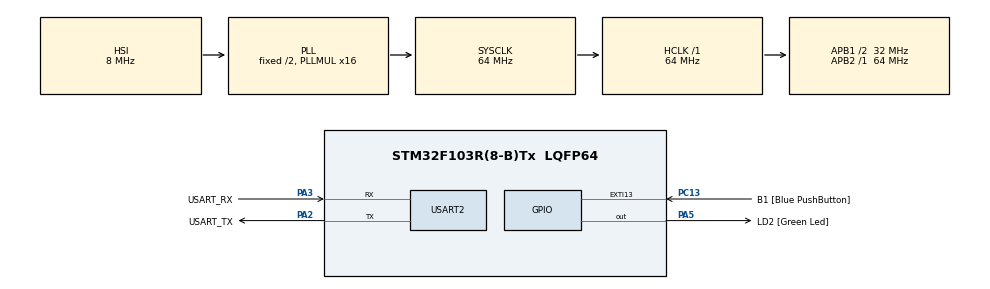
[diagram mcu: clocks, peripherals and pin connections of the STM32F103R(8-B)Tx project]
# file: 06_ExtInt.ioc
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Mcu.Family=STM32F1
Mcu.Name=STM32F103R(8-B)Tx
Mcu.Package=LQFP64
NVIC.EXTI15_10_IRQn=true\:0\:0\:false\:false\:true\:true\:true\:true
NVIC.PriorityGroup=NVIC_PRIORITYGROUP_4
PA13.GPIO_Label=TMS
PA13.Mode=Serial_Wire
PA13.Signal=SYS_JTMS-SWDIO
PA14.GPIO_Label=TCK
PA14.Mode=Serial_Wire
PA14.Signal=SYS_JTCK-SWCLK
PA2.GPIO_Label=USART_TX
PA2.GPIO_Mode=GPIO_MODE_AF_PP
PA2.GPIO_PuPd=GPIO_NOPULL
PA2.GPIO_Speed=GPIO_SPEED_FREQ_LOW
PA2.Mode=Asynchronous
PA2.Signal=USART2_TX
PA3.GPIO_Label=USART_RX
PA3.GPIO_Mode=GPIO_MODE_INPUT
PA3.GPIO_PuPd=GPIO_NOPULL
PA3.Mode=Asynchronous
PA3.Signal=USART2_RX
PA5.GPIO_Label=LD2 [Green Led]
PA5.GPIO_ModeDefaultOutputPP=GPIO_MODE_OUTPUT_PP
PA5.GPIO_PuPd=GPIO_NOPULL
PA5.GPIO_Speed=GPIO_SPEED_FREQ_LOW
PA5.Signal=GPIO_Output
PB3.GPIO_Label=SWO
PB3.Signal=SYS_JTDO-TRACESWO
PC13-TAMPER-RTC.GPIO_Label=B1 [Blue PushButton]
PC13-TAMPER-RTC.GPIO_ModeDefaultEXTI=GPIO_MODE_IT_FALLING
PC13-TAMPER-RTC.GPIO_PuPd=GPIO_NOPULL
PC13-TAMPER-RTC.Signal=GPXTI13
PC14-OSC32_IN.Mode=LSE-External-Oscillator
PC14-OSC32_IN.Signal=RCC_OSC32_IN
PC15-OSC32_OUT.Mode=LSE-External-Oscillator
PC15-OSC32_OUT.Signal=RCC_OSC32_OUT
PD0-OSC_IN.Mode=HSE-External-Clock-Source
PD0-OSC_IN.Signal=RCC_OSC_IN
PD1-OSC_OUT.Mode=HSE-External-Clock-Source
PD1-OSC_OUT.Signal=RCC_OSC_OUT
ProjectManager.HeapSize=0x200
ProjectManager.StackSize=0x400
ProjectManager.TargetToolchain=STM32CubeIDE
RCC.AHBFreq_Value=64000000
RCC.APB1CLKDivider=RCC_HCLK_DIV2
RCC.APB1Freq_Value=32000000
RCC.APB1TimFreq_Value=64000000
RCC.APB2Freq_Value=64000000
RCC.APB2TimFreq_Value=64000000
RCC.HCLKFreq_Value=64000000
RCC.PLLMUL=RCC_PLL_MUL16
RCC.RTCClockSelection=RCC_RTCCLKSOURCE_LSE
RCC.SYSCLKFreq_VALUE=64000000
RCC.SYSCLKSource=RCC_SYSCLKSOURCE_PLLCLK
RCC.USBFreq_Value=64000000
USART2.VirtualMode=VM_ASYNC
board=NUCLEO-F103RB

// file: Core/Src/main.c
/* USER CODE BEGIN Header */
/**
  ******************************************************************************
  * @file           : main.c
  * @brief          : Main program body
  ******************************************************************************
  * @attention
  *
  * Copyright (c) 2026 STMicroelectronics.
  * All rights reserved.
  *
  * This software is licensed under terms that can be found in the LICENSE file
  * in the root directory of this software component.
  * If no LICENSE file comes with this software, it is provided AS-IS.
  *
  ******************************************************************************
  */
/**
 * 06_ExtInt  —  [계층: HAL + EXTI/NVIC]  버튼(B1, PC13) 외부 인터럽트로 LED(LD2) 토글
 *
 * 신호 경로: PC13 -> EXTI13 (하강 에지) -> NVIC EXTI15_10_IRQn -> ISR -> HAL 콜백
 *
 * 하드웨어 대응 (RM0008)
 *   AFIO_EXTICR4  : EXTI13 의 입력 포트를 PC 로 선택
 *   EXTI_IMR / EXTI_FTSR : EXTI13 인터럽트 마스크 해제 / 하강 에지 트리거
 *   EXTI_PR       : 펜딩 비트 (HAL_GPIO_EXTI_IRQHandler 가 1을 써서 지움)
 *   NVIC_ISER     : EXTI15_10_IRQn 허용 (HAL_NVIC_EnableIRQ)
 *
 * ISR 과 콜백의 구분
 *   EXTI15_10_IRQHandler()     (stm32f1xx_it.c) : 진짜 ISR. HAL_GPIO_EXTI_IRQHandler() 를 호출
 *   HAL_GPIO_EXTI_Callback()   (이 파일)        : 사용자 콜백. ISR 문맥에서 실행되므로 짧게 끝낼 것
 */
/* USER CODE END Header */
#include "main.h"

UART_HandleTypeDef huart2;

void SystemClock_Config(void);
static void MX_GPIO_Init(void);
static void MX_USART2_UART_Init(void);

int main(void)
{

  /* MCU Configuration--------------------------------------------------------*/

  /* Reset of all peripherals, Initializes the Flash interface and the Systick. */
  HAL_Init();

  /* Configure the system clock */
  SystemClock_Config();

  /* Initialize all configured peripherals */
  MX_GPIO_Init();
  MX_USART2_UART_Init();

  /* Infinite loop */
  while (1)
  {

  }
}

void SystemClock_Config(void)
{
  RCC_OscInitTypeDef RCC_OscInitStruct = {0};
  RCC_ClkInitTypeDef RCC_ClkInitStruct = {0};

  /** Initializes the RCC Oscillators according to the specified parameters
  * in the RCC_OscInitTypeDef structure.
  */
  RCC_OscInitStruct.OscillatorType = RCC_OSCILLATORTYPE_HSI;
  RCC_OscInitStruct.HSIState = RCC_HSI_ON;
  RCC_OscInitStruct.HSICalibrationValue = RCC_HSICALIBRATION_DEFAULT;
  RCC_OscInitStruct.PLL.PLLState = RCC_PLL_ON;
  RCC_OscInitStruct.PLL.PLLSource = RCC_PLLSOURCE_HSI_DIV2;
  RCC_OscInitStruct.PLL.PLLMUL = RCC_PLL_MUL16;
  if (HAL_RCC_OscConfig(&RCC_OscInitStruct) != HAL_OK)
  {
    Error_Handler();
  }

  /** Initializes the CPU, AHB and APB buses clocks
  */
  RCC_ClkInitStruct.ClockType = RCC_CLOCKTYPE_HCLK|RCC_CLOCKTYPE_SYSCLK
                              |RCC_CLOCKTYPE_PCLK1|RCC_CLOCKTYPE_PCLK2;
  RCC_ClkInitStruct.SYSCLKSource = RCC_SYSCLKSOURCE_PLLCLK;
  RCC_ClkInitStruct.AHBCLKDivider = RCC_SYSCLK_DIV1;
  RCC_ClkInitStruct.APB1CLKDivider = RCC_HCLK_DIV2;
  RCC_ClkInitStruct.APB2CLKDivider = RCC_HCLK_DIV1;

  if (HAL_RCC_ClockConfig(&RCC_ClkInitStruct, FLASH_LATENCY_2) != HAL_OK)
  {
    Error_Handler();
  }
}

static void MX_USART2_UART_Init(void)
{

  huart2.Instance = USART2;
  huart2.Init.BaudRate = 115200;
  huart2.Init.WordLength = UART_WORDLENGTH_8B;
  huart2.Init.StopBits = UART_STOPBITS_1;
  huart2.Init.Parity = UART_PARITY_NONE;
  huart2.Init.Mode = UART_MODE_TX_RX;
  huart2.Init.HwFlowCtl = UART_HWCONTROL_NONE;
  huart2.Init.OverSampling = UART_OVERSAMPLING_16;
  if (HAL_UART_Init(&huart2) != HAL_OK)
  {
    Error_Handler();
  }

}

static void MX_GPIO_Init(void)
{
  GPIO_InitTypeDef GPIO_InitStruct = {0};

  /* GPIO Ports Clock Enable */
  __HAL_RCC_GPIOC_CLK_ENABLE();
  __HAL_RCC_GPIOD_CLK_ENABLE();
  __HAL_RCC_GPIOA_CLK_ENABLE();
  __HAL_RCC_GPIOB_CLK_ENABLE();

  /*Configure GPIO pin Output Level */
  HAL_GPIO_WritePin(LD2_GPIO_Port, LD2_Pin, GPIO_PIN_RESET);

  /*Configure GPIO pin : B1_Pin */
  GPIO_InitStruct.Pin = B1_Pin;
  GPIO_InitStruct.Mode = GPIO_MODE_IT_FALLING;
  GPIO_InitStruct.Pull = GPIO_NOPULL;
  HAL_GPIO_Init(B1_GPIO_Port, &GPIO_InitStruct);

  /*Configure GPIO pin : LD2_Pin */
  GPIO_InitStruct.Pin = LD2_Pin;
  GPIO_InitStruct.Mode = GPIO_MODE_OUTPUT_PP;
  GPIO_InitStruct.Pull = GPIO_NOPULL;
  GPIO_InitStruct.Speed = GPIO_SPEED_FREQ_LOW;
  HAL_GPIO_Init(LD2_GPIO_Port, &GPIO_InitStruct);

  /* EXTI interrupt init*/
  HAL_NVIC_SetPriority(EXTI15_10_IRQn, 0, 0);
  HAL_NVIC_EnableIRQ(EXTI15_10_IRQn);

}

/* USER CODE BEGIN 4 */
/**
  * @brief  외부 인터럽트가 발생했을 때 HAL 라이브러리가 자동으로 호출하는 콜백 함수
  * @param  GPIO_Pin: 인터럽트를 유발한 핀 번호
  */
void HAL_GPIO_EXTI_Callback(uint16_t GPIO_Pin)
{
  // 1. 여러 인터럽트 핀 중 현재 발생한 인터럽트가 버튼 핀(B1_Pin)인지 확인
  if (GPIO_Pin == B1_Pin)
  {
    /* * [생체신호처리/임베디드 핵심 팁]
     * 인터럽트 서비스 루틴(ISR) 내부에서는 HAL_Delay()나 무거운 연산을 절대 사용하면 안 됨.
     * 여기서는 플래그 변수만 토글하거나, 아래와 같이 아주 가벼운 하드웨어 제어만 수행하는 것이 정석임.
     */

    // 버튼이 눌릴 때마다 LD2 LED 상태를 반전
    HAL_GPIO_TogglePin(LD2_GPIO_Port, LD2_Pin);
  }
}
/* USER CODE END 4 */

void Error_Handler(void)
{
  __disable_irq();
  while (1)
  {
  }
}
